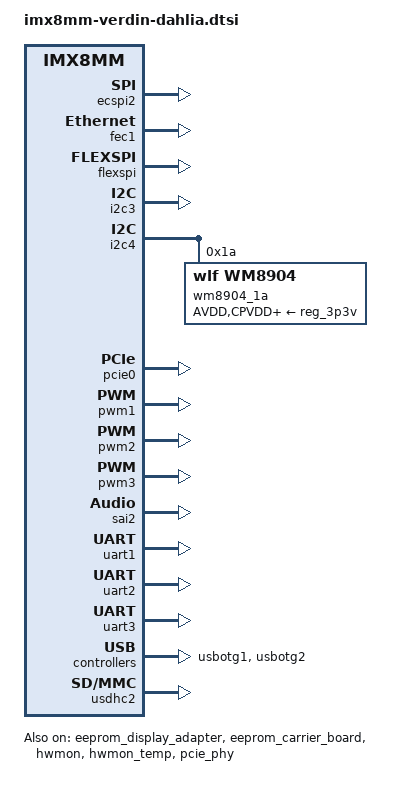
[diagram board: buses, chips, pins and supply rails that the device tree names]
/ {
	sound_card: sound-card {
		compatible = "simple-audio-card";
		simple-audio-card,bitclock-master = <&dailink_master>;
		simple-audio-card,format = "i2s";
		simple-audio-card,frame-master = <&dailink_master>;
		simple-audio-card,mclk-fs = <256>;
		simple-audio-card,name = "imx8mm-wm8904";
		simple-audio-card,routing =
			"Headphone Jack", "HPOUTL",
			"Headphone Jack", "HPOUTR",
			"IN2L", "Line In Jack",
			"IN2R", "Line In Jack",
			"Headphone Jack", "MICBIAS",
			"IN1L", "Headphone Jack";
		simple-audio-card,widgets =
			"Microphone", "Headphone Jack",
			"Headphone", "Headphone Jack",
			"Line", "Line In Jack";
		dailink_master: simple-audio-card,codec {
			clocks = <&clk IMX8MM_CLK_SAI2_ROOT>;
			sound-dai = <&wm8904_1a>;
		};
		simple-audio-card,cpu {
			sound-dai = <&sai2>;
		};
	};
};
&ecspi2 {
	status = "okay";
};
&eeprom_display_adapter {
	status = "okay";
};
&eeprom_carrier_board {
	status = "okay";
};
&fec1 {
	status = "okay";
};
&flexspi {
	status = "okay";
};
&hwmon {
	status = "okay";
};
&hwmon_temp {
	vs-supply = <&reg_1p8v>;
	status = "okay";
};
&i2c3 {
	status = "okay";
};
&i2c4 {
	status = "okay";
	wm8904_1a: audio-codec@1a {
		compatible = "wlf,wm8904";
		AVDD-supply = <&reg_3p3v>;
		clocks = <&clk IMX8MM_CLK_SAI2_ROOT>;
		clock-names = "mclk";
		CPVDD-supply = <&reg_3p3v>;
		DBVDD-supply = <&reg_3p3v>;
		DCVDD-supply = <&reg_3p3v>;
		MICVDD-supply = <&reg_3p3v>;
		reg = <0x1a>;
		#sound-dai-cells = <0>;
	};
};
&pcie0 {
	status = "okay";
};
&pcie_phy {
	status = "okay";
};
&pwm1 {
	status = "okay";
};
&pwm2 {
	status = "okay";
};
&pwm3 {
	status = "okay";
};
&sai2 {
	status = "okay";
};
&uart1 {
	status = "okay";
};
&uart2 {
	status = "okay";
};
&uart3 {
	status = "okay";
};
&usbotg1 {
	disable-over-current;
	status = "okay";
};
&usbotg2 {
	disable-over-current;
	status = "okay";
};
&usdhc2 {
	status = "okay";
};
